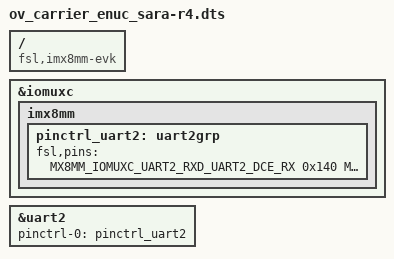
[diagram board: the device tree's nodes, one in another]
/**
 * Portenta-M8 dtb overlay file
 * Arduino 2021
 * Enable SARA-R4 modem serial port on Arduino eNUC carrier board
 * no RTS CTS only TX RX.
 * In order for the modem to work ov_carrier_enuc_usbfs overlay need to be included.
 * Gpios:
 * - Reset pin active low
 * - Power on pin active high
 */

/dts-v1/;
/plugin/;

#include "imx8mm-pinfunc.h"

/ {
	compatible = "fsl,imx8mm-evk", "fsl,imx8mm";

	fragment@0 {
		target = <&iomuxc>;
		__overlay__ {
			imx8mm {
				pinctrl_uart2: uart2grp {
					fsl,pins = <
						MX8MM_IOMUXC_UART2_RXD_UART2_DCE_RX       0x140
						MX8MM_IOMUXC_UART2_TXD_UART2_DCE_TX       0x140
						MX8MM_IOMUXC_GPIO1_IO09_GPIO1_IO9    0xC0000041 /* RST active low */
						MX8MM_IOMUXC_GPIO1_IO11_GPIO1_IO11   0xC0000041 /* POWER_ON active high */
					>;
				};
			};
		};
	};

	fragment@1 {
		target = <&uart2>;
		__overlay__ {
			pinctrl-names = "default";
			pinctrl-0 = <&pinctrl_uart2>;
			status = "okay";
		};
	};
};
